# SWM261 register map
File version: 1.0
CPU: CM0 r1p0, little endian, 2 interrupt priority bits
Registers are 32-bit, read-write, no defined reset value unless marked. A register's access mark holds for its fields unless they carry their own. Offsets are from the block's base; [hi:lo] are bit positions; lines under a group give offsets from that group; {n}, {i} and the like mark numbered series; 'fields as' and 'values as' point back to an identical list.

## TIMR0 — Registers group
Base 0x40043800
Same registers: TIMR1 0x40043840, TIMR2 0x40043880, BTIMR0 0x40044000, BTIMR1 0x40044040, BTIMR2 0x40044080, BTIMR3 0x400440C0
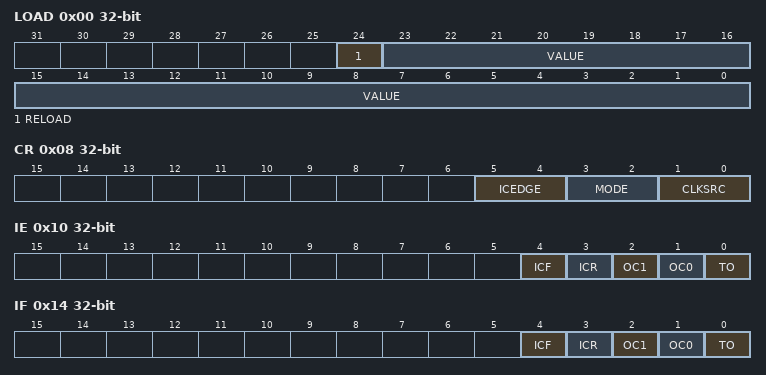
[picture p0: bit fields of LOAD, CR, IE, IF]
0x00 LOAD
  [24] RELOAD, [23:0] VALUE
0x04 VALUE ro
0x08 CR
  [5:4] ICEDGE, [3:2] MODE, [1:0] CLKSRC
0x10 IE
  [4] ICF, [3] ICR, [2] OC1, [1] OC0, [0] TO
0x14 IF
  [4] ICF, [3] ICR, [2] OC1, [1] OC0, [0] TO
0x18 HALT
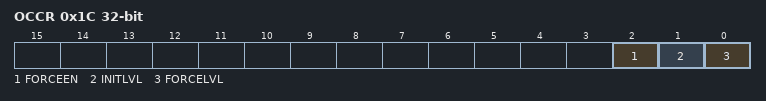
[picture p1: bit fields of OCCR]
0x1C OCCR
  [2] FORCEEN, [1] INITLVL, [0] FORCELVL
0x20 OCMAT
0x28 ICLOW
0x2C ICHIGH
0x30 PREDIV

## TIMRG — Registers group
Base 0x40043C00
Same registers: BTIMRG 0x40044400
0x00 HALLIE
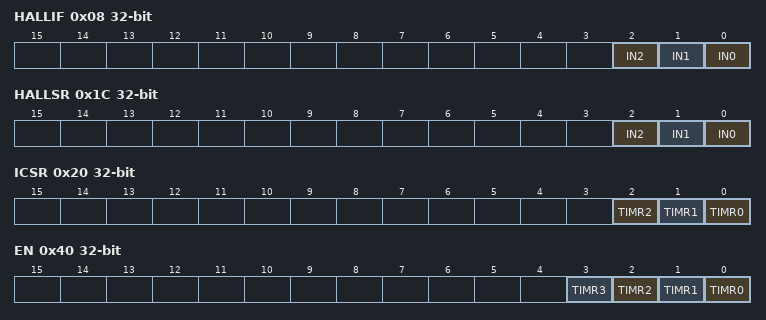
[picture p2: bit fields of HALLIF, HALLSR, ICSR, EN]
0x08 HALLIF
  [2] IN2, [1] IN1, [0] IN0
0x0C HALLEN
0x10 HALLDR
0x1C HALLSR
  [2] IN2, [1] IN1, [0] IN0
0x20 ICSR
  [2] TIMR2, [1] TIMR1, [0] TIMR0
0x40 EN
  [n] TIMR{n} (n=0..3)

## UART0 — Registers group
Base 0x40040000
Same registers: UART1 0x40040800
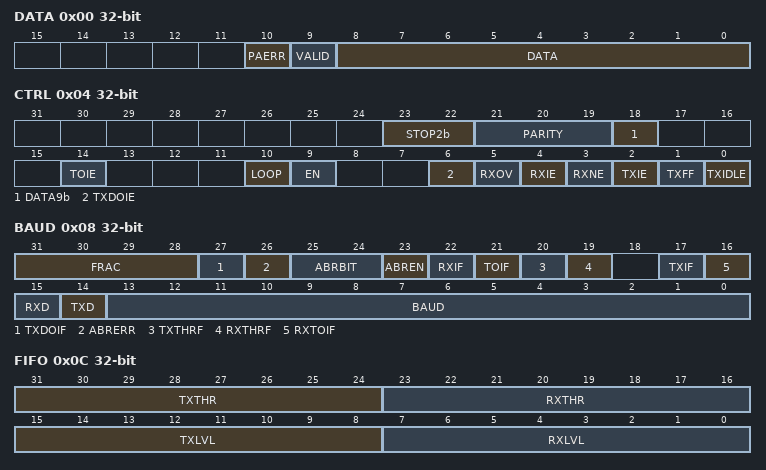
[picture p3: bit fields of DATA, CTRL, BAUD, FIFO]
0x00 DATA
  [10] PAERR, [9] VALID, [8:0] DATA
0x04 CTRL
  [23:22] STOP2b, [21:19] PARITY, [18] DATA9b, [14] TOIE, [10] LOOP, [9] EN, [6] TXDOIE, [5] RXOV, [4] RXIE, [3] RXNE, [2] TXIE, [1] TXFF, [0] TXIDLE
0x08 BAUD
  [31:28] FRAC, [27] TXDOIF, [26] ABRERR, [25:24] ABRBIT, [23] ABREN, [22] RXIF, [21] TOIF, [20] TXTHRF, [19] RXTHRF, [17] TXIF, [16] RXTOIF, [15] RXD, [14] TXD, [13:0] BAUD
0x0C FIFO
  [31:24] TXTHR, [23:16] RXTHR, [15:8] TXLVL, [7:0] RXLVL
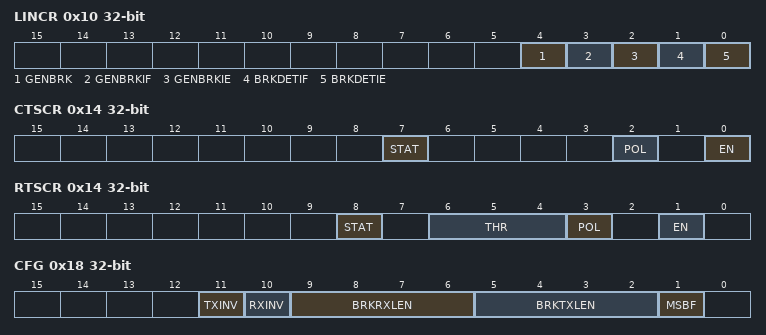
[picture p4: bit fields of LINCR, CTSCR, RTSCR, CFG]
0x10 LINCR
  [4] GENBRK, [3] GENBRKIF, [2] GENBRKIE, [1] BRKDETIF, [0] BRKDETIE
0x14 CTSCR
  [7] STAT, [2] POL, [0] EN
0x14 RTSCR (alternate view of CTSCR)
  [8] STAT, [6:4] THR, [3] POL, [1] EN
0x18 CFG
  [11] TXINV, [10] RXINV, [9:6] BRKRXLEN, [5:2] BRKTXLEN, [1] MSBF
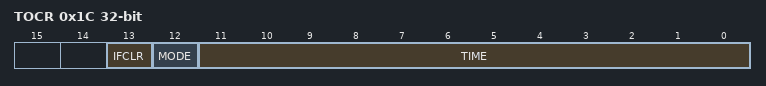
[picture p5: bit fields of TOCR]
0x1C TOCR
  [13] IFCLR, [12] MODE, [11:0] TIME

## USART0 — Registers group
Base 0x40047000
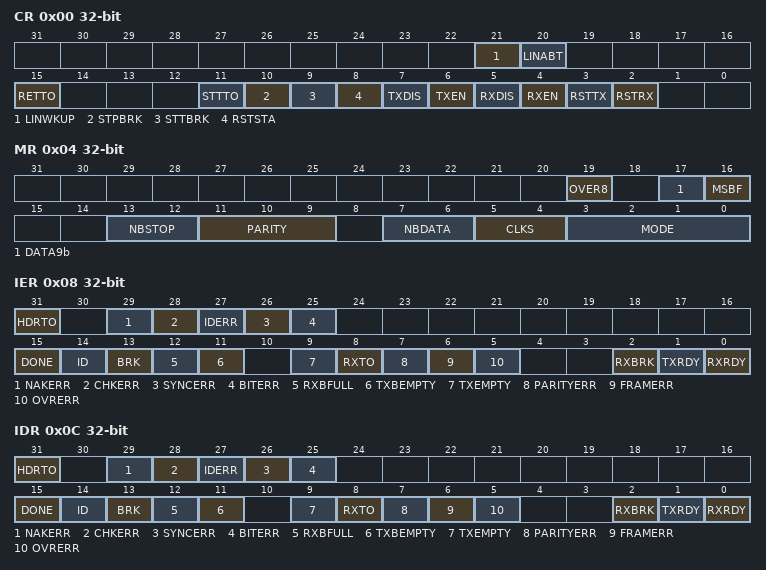
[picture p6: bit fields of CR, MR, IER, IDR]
0x00 CR wo
  [21] LINWKUP, [20] LINABT, [15] RETTO, [11] STTTO, [10] STPBRK, [9] STTBRK, [8] RSTSTA, [7] TXDIS, [6] TXEN, [5] RXDIS, [4] RXEN, [3] RSTTX, [2] RSTRX
0x04 MR
  [19] OVER8, [17] DATA9b, [16] MSBF, [13:12] NBSTOP, [11:9] PARITY, [7:6] NBDATA, [5:4] CLKS, [3:0] MODE
0x08 IER wo
  [31] HDRTO, [29] NAKERR, [28] CHKERR, [27] IDERR, [26] SYNCERR, [25] BITERR, [15] DONE, [14] ID, [13] BRK, [12] RXBFULL, [11] TXBEMPTY, [9] TXEMPTY, [8] RXTO, [7] PARITYERR, [6] FRAMERR, [5] OVRERR, [2] RXBRK, [1] TXRDY, [0] RXRDY
0x0C IDR wo
  fields as IER
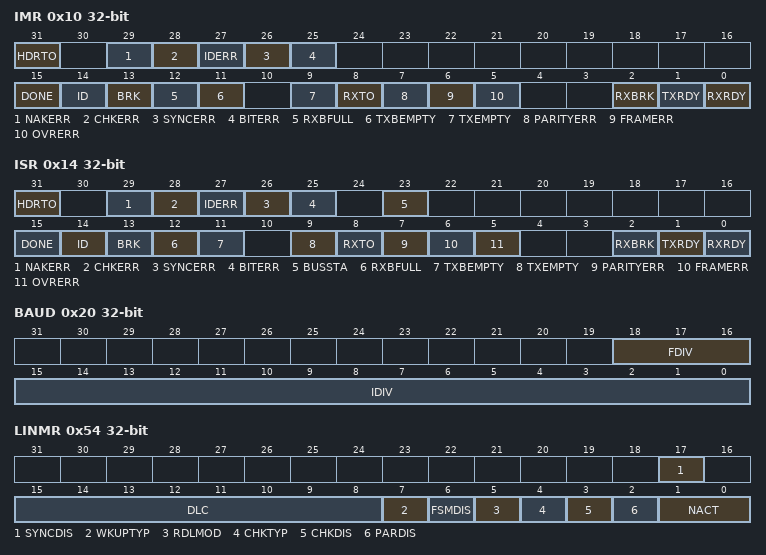
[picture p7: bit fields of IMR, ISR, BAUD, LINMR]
0x10 IMR ro
  fields as IER
0x14 ISR ro
  [31] HDRTO, [29] NAKERR, [28] CHKERR, [27] IDERR, [26] SYNCERR, [25] BITERR, [23] BUSSTA, [15] DONE, [14] ID, [13] BRK, [12] RXBFULL, [11] TXBEMPTY, [9] TXEMPTY, [8] RXTO, [7] PARITYERR, [6] FRAMERR, [5] OVRERR, [2] RXBRK, [1] TXRDY, [0] RXRDY
0x18 RHR ro
  [8:0] DATA
0x1C THR wo
  [8:0] DATA
0x20 BAUD
  [18:16] FDIV, [15:0] IDIV
0x24 RXTO
0x54 LINMR
  [17] SYNCDIS, [15:8] DLC, [7] WKUPTYP, [6] FSMDIS, [5] RDLMOD, [4] CHKTYP, [3] CHKDIS, [2] PARDIS, [1:0] NACT
0x58 LINID
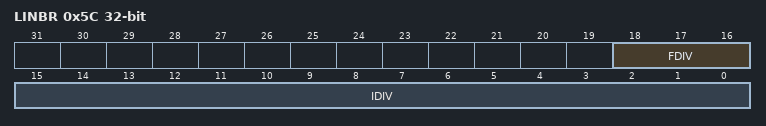
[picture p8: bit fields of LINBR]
0x5C LINBR ro
  [18:16] FDIV, [15:0] IDIV

## QSPI0 — Registers group
Base 0x40001800
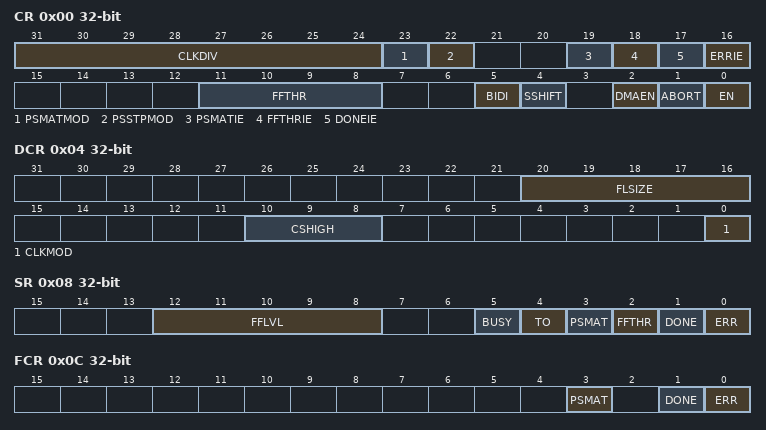
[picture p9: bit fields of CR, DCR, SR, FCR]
0x00 CR
  [31:24] CLKDIV, [23] PSMATMOD, [22] PSSTPMOD, [19] PSMATIE, [18] FFTHRIE, [17] DONEIE, [16] ERRIE, [11:8] FFTHR, [5] BIDI, [4] SSHIFT, [2] DMAEN, [1] ABORT, [0] EN
0x04 DCR
  [20:16] FLSIZE, [10:8] CSHIGH, [0] CLKMOD
0x08 SR
  [12:8] FFLVL, [5] BUSY, [4] TO, [3] PSMAT, [2] FFTHR, [1] DONE, [0] ERR
0x0C FCR
  [3] PSMAT, [1] DONE, [0] ERR
0x10 DLR
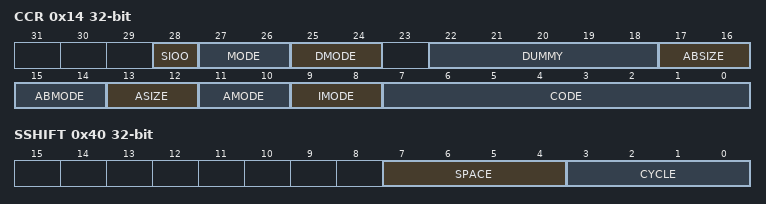
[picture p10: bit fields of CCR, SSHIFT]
0x14 CCR
  [28] SIOO, [27:26] MODE, [25:24] DMODE, [22:18] DUMMY, [17:16] ABSIZE, [15:14] ABMODE, [13:12] ASIZE, [11:10] AMODE, [9:8] IMODE, [7:0] CODE
0x18 AR
0x1C ABR
0x20 DRB
0x24 PSMSK
0x28 PSMAT
0x2C PSITV
0x40 SSHIFT
  [7:4] SPACE, [3:0] CYCLE

## SPI0 — Registers group
Base 0x40041800
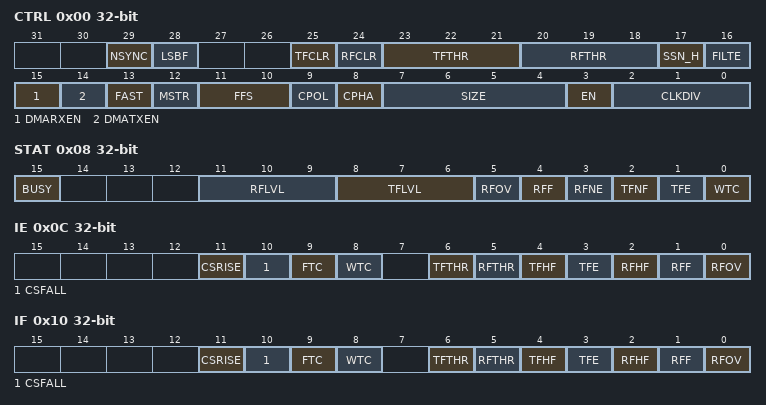
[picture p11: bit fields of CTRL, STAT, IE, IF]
0x00 CTRL
  [29] NSYNC, [28] LSBF, [25] TFCLR, [24] RFCLR, [23:21] TFTHR, [20:18] RFTHR, [17] SSN_H, [16] FILTE, [15] DMARXEN, [14] DMATXEN, [13] FAST, [12] MSTR, [11:10] FFS, [9] CPOL, [8] CPHA, [7:4] SIZE, [3] EN, [2:0] CLKDIV
0x04 DATA
0x08 STAT
  [15] BUSY, [11:9] RFLVL, [8:6] TFLVL, [5] RFOV, [4] RFF, [3] RFNE, [2] TFNF, [1] TFE, [0] WTC
0x0C IE
  [11] CSRISE, [10] CSFALL, [9] FTC, [8] WTC, [6] TFTHR, [5] RFTHR, [4] TFHF, [3] TFE, [2] RFHF, [1] RFF, [0] RFOV
0x10 IF
  fields as IE
